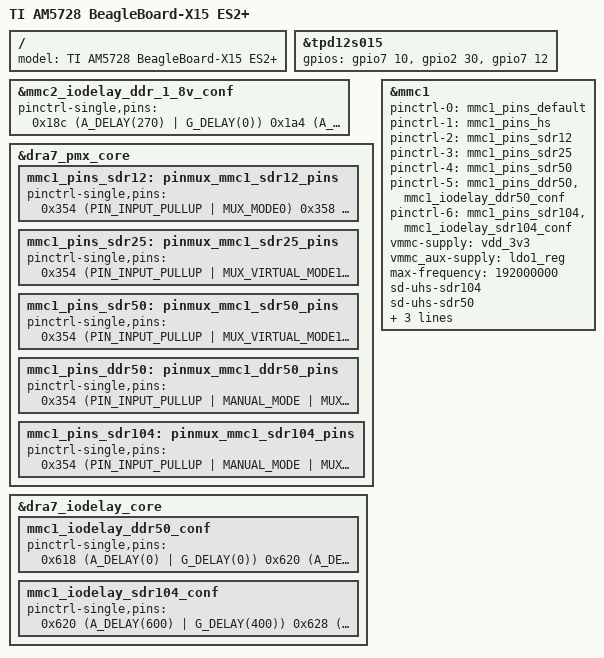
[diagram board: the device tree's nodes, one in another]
/*
 * Copyright (C) 2016 Texas Instruments Incorporated - http://www.ti.com/
 *
 * This program is free software; you can redistribute it and/or modify
 * it under the terms of the GNU General Public License version 2 as
 * published by the Free Software Foundation.
 */

#include "am57xx-beagle-x15.dts"
/ {
	model = "TI AM5728 BeagleBoard-X15 ES2+";
};

&tpd12s015 {
		gpios = <&gpio7 10 GPIO_ACTIVE_HIGH>,	/* gpio7_10, CT CP HPD */
			<&gpio2 30 GPIO_ACTIVE_HIGH>,	/* gpio2_30, LS OE (for new boards) */
			<&gpio7 12 GPIO_ACTIVE_HIGH>;	/* gpio7_12/sp1_cs2, HPD */
};

&mmc2_iodelay_ddr_1_8v_conf {
	pinctrl-single,pins = <
		0x18c (A_DELAY(270) | G_DELAY(0))	/* CFG_GPMC_A19_IN */
		0x1a4 (A_DELAY(0) | G_DELAY(0))		/* CFG_GPMC_A20_IN */
		0x1b0 (A_DELAY(170) | G_DELAY(0))	/* CFG_GPMC_A21_IN */
		0x1bc (A_DELAY(758) | G_DELAY(0))	/* CFG_GPMC_A22_IN */
		0x1c8 (A_DELAY(0) | G_DELAY(0))		/* CFG_GPMC_A23_IN */
		0x1d4 (A_DELAY(81) | G_DELAY(0))	/* CFG_GPMC_A24_IN */
		0x1e0 (A_DELAY(286) | G_DELAY(0))	/* CFG_GPMC_A25_IN */
		0x1ec (A_DELAY(0) | G_DELAY(0))		/* CFG_GPMC_A26_IN */
		0x1f8 (A_DELAY(123) | G_DELAY(0))	/* CFG_GPMC_A27_IN */
		0x360 (A_DELAY(346) | G_DELAY(0))	/* CFG_GPMC_CS1_IN */
		0x190 (A_DELAY(0) | G_DELAY(0))		/* CFG_GPMC_A19_OEN */
		0x194 (A_DELAY(55) | G_DELAY(0))	/* CFG_GPMC_A19_OUT */
		0x1a8 (A_DELAY(0) | G_DELAY(0))		/* CFG_GPMC_A20_OEN */
		0x1ac (A_DELAY(422) | G_DELAY(0))	/* CFG_GPMC_A20_OUT */
		0x1b4 (A_DELAY(642) | G_DELAY(0))	/* CFG_GPMC_A21_OEN */
		0x1b8 (A_DELAY(0) | G_DELAY(0))		/* CFG_GPMC_A21_OUT */
		0x1c0 (A_DELAY(0) | G_DELAY(0))		/* CFG_GPMC_A22_OEN */
		0x1c4 (A_DELAY(128) | G_DELAY(0))	/* CFG_GPMC_A22_OUT */
		0x1d0 (A_DELAY(0) | G_DELAY(0))		/* CFG_GPMC_A23_OUT */
		0x1d8 (A_DELAY(0) | G_DELAY(0))		/* CFG_GPMC_A24_OEN */
		0x1dc (A_DELAY(395) | G_DELAY(0))	/* CFG_GPMC_A24_OUT */
		0x1e4 (A_DELAY(0) | G_DELAY(0))		/* CFG_GPMC_A25_OEN */
		0x1e8 (A_DELAY(0) | G_DELAY(0))		/* CFG_GPMC_A25_OUT */
		0x1f0 (A_DELAY(623) | G_DELAY(0))	/* CFG_GPMC_A26_OEN */
		0x1f4 (A_DELAY(0) | G_DELAY(0))		/* CFG_GPMC_A26_OUT */
		0x1fc (A_DELAY(54) | G_DELAY(0))	/* CFG_GPMC_A27_OEN */
		0x200 (A_DELAY(0) | G_DELAY(0))		/* CFG_GPMC_A27_OUT */
		0x364 (A_DELAY(0) | G_DELAY(0))		/* CFG_GPMC_CS1_OEN */
		0x368 (A_DELAY(0) | G_DELAY(0))		/* CFG_GPMC_CS1_OUT */
	>;
};

&dra7_pmx_core {
	mmc1_pins_sdr12: pinmux_mmc1_sdr12_pins {
		pinctrl-single,pins = <
			0x354 (PIN_INPUT_PULLUP | MUX_MODE0)	/* mmc1_clk.clk */
			0x358 (PIN_INPUT_PULLUP | MUX_MODE0)	/* mmc1_cmd.cmd */
			0x35c (PIN_INPUT_PULLUP | MUX_MODE0)	/* mmc1_dat0.dat0 */
			0x360 (PIN_INPUT_PULLUP | MUX_MODE0)	/* mmc1_dat1.dat1 */
			0x364 (PIN_INPUT_PULLUP | MUX_MODE0)	/* mmc1_dat2.dat2 */
			0x368 (PIN_INPUT_PULLUP | MUX_MODE0)	/* mmc1_dat3.dat3 */
		>;
	};

	mmc1_pins_sdr25: pinmux_mmc1_sdr25_pins {
		pinctrl-single,pins = <
			0x354 (PIN_INPUT_PULLUP | MUX_VIRTUAL_MODE11 | MUX_MODE0)	/* mmc1_clk.clk */
			0x358 (PIN_INPUT_PULLUP | MUX_VIRTUAL_MODE11 | MUX_MODE0)	/* mmc1_cmd.cmd */
			0x35c (PIN_INPUT_PULLUP | MUX_VIRTUAL_MODE11 | MUX_MODE0)	/* mmc1_dat0.dat0 */
			0x360 (PIN_INPUT_PULLUP | MUX_VIRTUAL_MODE11 | MUX_MODE0)	/* mmc1_dat1.dat1 */
			0x364 (PIN_INPUT_PULLUP | MUX_VIRTUAL_MODE11 | MUX_MODE0)	/* mmc1_dat2.dat2 */
			0x368 (PIN_INPUT_PULLUP | MUX_VIRTUAL_MODE11 | MUX_MODE0)	/* mmc1_dat3.dat3 */
		>;
	};

	mmc1_pins_sdr50: pinmux_mmc1_sdr50_pins {
		pinctrl-single,pins = <
			0x354 (PIN_INPUT_PULLUP | MUX_VIRTUAL_MODE10 | MUX_MODE0)	/* mmc1_clk.clk */
			0x358 (PIN_INPUT_PULLUP | MUX_VIRTUAL_MODE10 | MUX_MODE0)	/* mmc1_cmd.cmd */
			0x35c (PIN_INPUT_PULLUP | MUX_VIRTUAL_MODE10 | MUX_MODE0)	/* mmc1_dat0.dat0 */
			0x360 (PIN_INPUT_PULLUP | MUX_VIRTUAL_MODE10 | MUX_MODE0)	/* mmc1_dat1.dat1 */
			0x364 (PIN_INPUT_PULLUP | MUX_VIRTUAL_MODE10 | MUX_MODE0)	/* mmc1_dat2.dat2 */
			0x368 (PIN_INPUT_PULLUP | MUX_VIRTUAL_MODE10 | MUX_MODE0)	/* mmc1_dat3.dat3 */
		>;
	};

	mmc1_pins_ddr50: pinmux_mmc1_ddr50_pins {
		pinctrl-single,pins = <
			0x354 (PIN_INPUT_PULLUP | MANUAL_MODE | MUX_MODE0)	/* mmc1_clk.clk */
			0x358 (PIN_INPUT_PULLUP | MANUAL_MODE | MUX_MODE0)	/* mmc1_cmd.cmd */
			0x35c (PIN_INPUT_PULLUP | MANUAL_MODE | MUX_MODE0)	/* mmc1_dat0.dat0 */
			0x360 (PIN_INPUT_PULLUP | MANUAL_MODE | MUX_MODE0)	/* mmc1_dat1.dat1 */
			0x364 (PIN_INPUT_PULLUP | MANUAL_MODE | MUX_MODE0)	/* mmc1_dat2.dat2 */
			0x368 (PIN_INPUT_PULLUP | MANUAL_MODE | MUX_MODE0)	/* mmc1_dat3.dat3 */
		>;
	};

	mmc1_pins_sdr104: pinmux_mmc1_sdr104_pins {
		pinctrl-single,pins = <
			0x354 (PIN_INPUT_PULLUP | MANUAL_MODE | MUX_MODE0)	/* mmc1_clk.clk */
			0x358 (PIN_INPUT_PULLUP | MANUAL_MODE | MUX_MODE0)	/* mmc1_cmd.cmd */
			0x35c (PIN_INPUT_PULLUP | MANUAL_MODE | MUX_MODE0)	/* mmc1_dat0.dat0 */
			0x360 (PIN_INPUT_PULLUP | MANUAL_MODE | MUX_MODE0)	/* mmc1_dat1.dat1 */
			0x364 (PIN_INPUT_PULLUP | MANUAL_MODE | MUX_MODE0)	/* mmc1_dat2.dat2 */
			0x368 (PIN_INPUT_PULLUP | MANUAL_MODE | MUX_MODE0)	/* mmc1_dat3.dat3 */
		>;
	};
};

&dra7_iodelay_core {
	mmc1_iodelay_ddr50_conf: mmc1_iodelay_ddr50_conf {
		pinctrl-single,pins = <
			0x618 (A_DELAY(0) | G_DELAY(0))		/* CFG_MMC1_CLK_IN */
			0x620 (A_DELAY(1271) | G_DELAY(0))	/* CFG_MMC1_CLK_OUT */
			0x624 (A_DELAY(229) | G_DELAY(0))	/* CFG_MMC1_CMD_IN */
			0x628 (A_DELAY(0) | G_DELAY(0))		/* CFG_MMC1_CMD_OEN */
			0x62C (A_DELAY(0) | G_DELAY(0))		/* CFG_MMC1_CMD_OUT */
			0x630 (A_DELAY(850) | G_DELAY(0))	/* CFG_MMC1_DAT0_IN */
			0x634 (A_DELAY(0) | G_DELAY(0))		/* CFG_MMC1_DAT0_OEN */
			0x638 (A_DELAY(20) | G_DELAY(0))	/* CFG_MMC1_DAT0_OUT */
			0x63C (A_DELAY(468) | G_DELAY(0))	/* CFG_MMC1_DAT1_IN */
			0x640 (A_DELAY(0) | G_DELAY(0))		/* CFG_MMC1_DAT1_OEN */
			0x644 (A_DELAY(0) | G_DELAY(0))		/* CFG_MMC1_DAT1_OUT */
			0x648 (A_DELAY(466) | G_DELAY(0))	/* CFG_MMC1_DAT2_IN */
			0x64C (A_DELAY(0) | G_DELAY(0))		/* CFG_MMC1_DAT2_OEN */
			0x650 (A_DELAY(0) | G_DELAY(0))		/* CFG_MMC1_DAT2_OUT */
			0x654 (A_DELAY(399) | G_DELAY(0))	/* CFG_MMC1_DAT3_IN */
			0x658 (A_DELAY(0) | G_DELAY(0))		/* CFG_MMC1_DAT3_OEN */
			0x65C (A_DELAY(0) | G_DELAY(0))		/* CFG_MMC1_DAT3_OUT */
		>;
	};

	mmc1_iodelay_sdr104_conf: mmc1_iodelay_sdr104_conf {
		pinctrl-single,pins = <
			0x620 (A_DELAY(600) | G_DELAY(400))	/* CFG_MMC1_CLK_OUT */
			0x628 (A_DELAY(0) | G_DELAY(0))		/* CFG_MMC1_CMD_OEN */
			0x62c (A_DELAY(0) | G_DELAY(0))		/* CFG_MMC1_CMD_OUT */
			0x634 (A_DELAY(0) | G_DELAY(0))		/* CFG_MMC1_DAT0_OEN */
			0x638 (A_DELAY(30) | G_DELAY(0))	/* CFG_MMC1_DAT0_OUT */
			0x640 (A_DELAY(0) | G_DELAY(0))		/* CFG_MMC1_DAT1_OEN */
			0x644 (A_DELAY(0) | G_DELAY(0))		/* CFG_MMC1_DAT1_OUT */
			0x64c (A_DELAY(0) | G_DELAY(0))		/* CFG_MMC1_DAT2_OEN */
			0x650 (A_DELAY(0) | G_DELAY(0))		/* CFG_MMC1_DAT2_OUT */
			0x658 (A_DELAY(0) | G_DELAY(0))		/* CFG_MMC1_DAT3_OEN */
			0x65c (A_DELAY(0) | G_DELAY(0))		/* CFG_MMC1_DAT3_OUT */
		>;
	};
};

&mmc1 {
	pinctrl-names = "default", "hs", "sdr12", "sdr25", "sdr50", "ddr50", "sdr104";
	pinctrl-0 = <&mmc1_pins_default>;
	pinctrl-1 = <&mmc1_pins_hs>;
	pinctrl-2 = <&mmc1_pins_sdr12>;
	pinctrl-3 = <&mmc1_pins_sdr25>;
	pinctrl-4 = <&mmc1_pins_sdr50>;
	pinctrl-5 = <&mmc1_pins_ddr50 &mmc1_iodelay_ddr50_conf>;
	pinctrl-6 = <&mmc1_pins_sdr104 &mmc1_iodelay_sdr104_conf>;
	vmmc-supply = <&vdd_3v3>;
	vmmc_aux-supply = <&ldo1_reg>;
	max-frequency = <192000000>;
	sd-uhs-sdr104;
	sd-uhs-sdr50;
	sd-uhs-ddr50;
	sd-uhs-sdr25;
	sd-uhs-sdr12;
};
